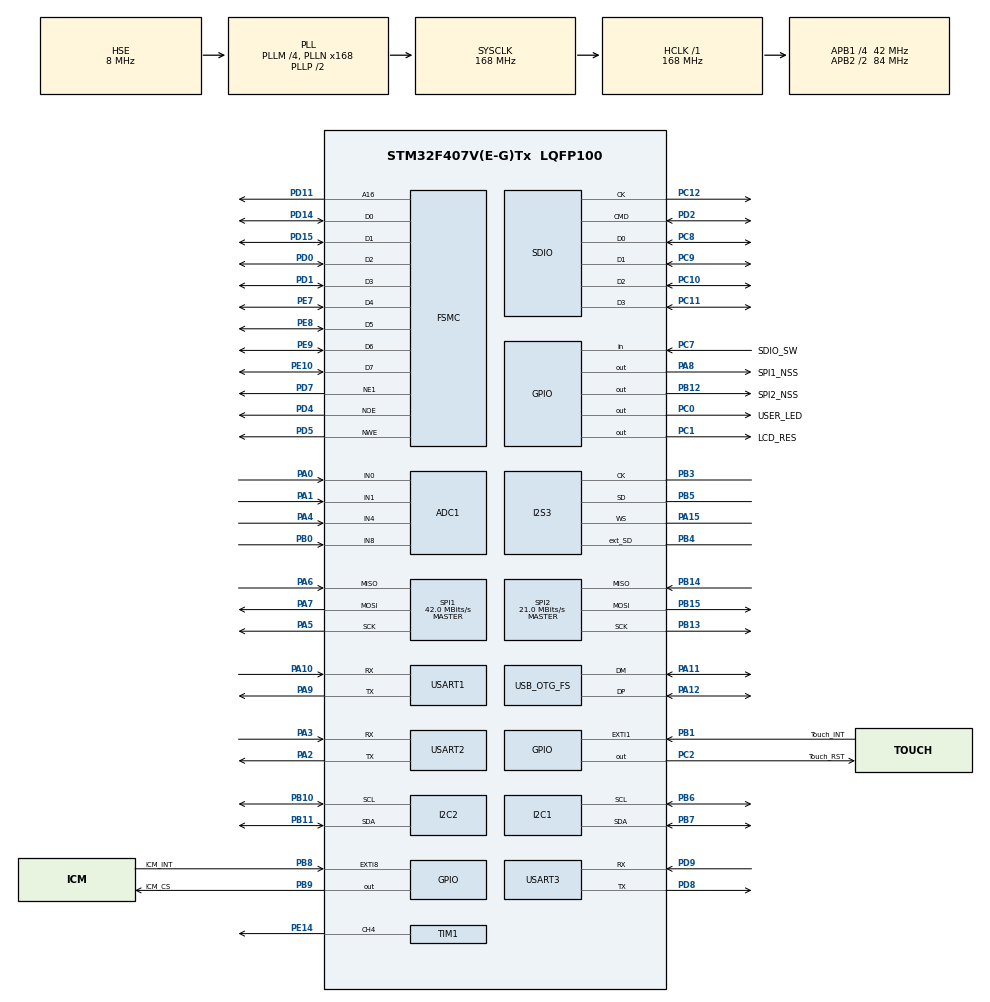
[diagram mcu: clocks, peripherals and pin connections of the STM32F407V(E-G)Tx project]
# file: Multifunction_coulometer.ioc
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ADC1.Channel-2\#ChannelRegularConversion=ADC_CHANNEL_0
ADC1.NbrOfConversionFlag=1
ADC1.Rank-2\#ChannelRegularConversion=1
ADC1.SamplingTime-2\#ChannelRegularConversion=ADC_SAMPLETIME_3CYCLES
ADC1.master=1
I2S3.ErrorAudioFreq=0.15 %
I2S3.FullDuplexMode=I2S_FULLDUPLEXMODE_ENABLE
I2S3.Instance=SPI$Index
I2S3.RealAudioFreq=8.012 KHz
I2S3.VirtualMode=I2S_MODE_MASTER
Mcu.Family=STM32F4
Mcu.Name=STM32F407V(E-G)Tx
Mcu.Package=LQFP100
NVIC.PriorityGroup=NVIC_PRIORITYGROUP_4
PA0-WKUP.Signal=ADCx_IN0
PA1.Signal=ADCx_IN1
PA10.Mode=Asynchronous
PA10.Signal=USART1_RX
PA11.Mode=Device_Only
PA11.Signal=USB_OTG_FS_DM
PA12.Mode=Device_Only
PA12.Signal=USB_OTG_FS_DP
PA13.Mode=Serial_Wire
PA13.Signal=SYS_JTMS-SWDIO
PA14.Mode=Serial_Wire
PA14.Signal=SYS_JTCK-SWCLK
PA15.Mode=Full_Duplex_Master
PA15.Signal=I2S3_WS
PA2.Mode=Asynchronous
PA2.Signal=USART2_TX
PA3.Mode=Asynchronous
PA3.Signal=USART2_RX
PA4.Signal=ADCx_IN4
PA5.Mode=Full_Duplex_Master
PA5.Signal=SPI1_SCK
PA6.Mode=Full_Duplex_Master
PA6.Signal=SPI1_MISO
PA7.Mode=Full_Duplex_Master
PA7.Signal=SPI1_MOSI
PA8.GPIO_Label=SPI1_NSS
PA8.Signal=GPIO_Output
PA9.Mode=Asynchronous
PA9.Signal=USART1_TX
PB0.Signal=ADCx_IN8
PB1.GPIO_Label=Touch_INT
PB1.Signal=GPXTI1
PB10.Mode=I2C
PB10.Signal=I2C2_SCL
PB11.Mode=I2C
PB11.Signal=I2C2_SDA
PB12.GPIO_Label=SPI2_NSS
PB12.Signal=GPIO_Output
PB13.Mode=Full_Duplex_Master
PB13.Signal=SPI2_SCK
PB14.Mode=Full_Duplex_Master
PB14.Signal=SPI2_MISO
PB15.Mode=Full_Duplex_Master
PB15.Signal=SPI2_MOSI
PB3.Mode=Full_Duplex_Master
PB3.Signal=I2S3_CK
PB4.Mode=Full_Duplex_Master
PB4.Signal=I2S3_ext_SD
PB5.Mode=Full_Duplex_Master
PB5.Signal=I2S3_SD
PB6.Mode=I2C
PB6.Signal=I2C1_SCL
PB7.Mode=I2C
PB7.Signal=I2C1_SDA
PB8.GPIO_Label=ICM_INT
PB8.Signal=GPXTI8
PB9.GPIO_Label=ICM_CS
PB9.Signal=GPIO_Output
PC0.GPIO_Label=USER_LED
PC0.GPIO_ModeDefaultOutputPP=GPIO_MODE_OUTPUT_PP
PC0.GPIO_PuPd=GPIO_PULLUP
PC0.GPIO_Speed=GPIO_SPEED_FREQ_VERY_HIGH
PC0.PinState=GPIO_PIN_SET
PC0.Signal=GPIO_Output
PC1.GPIO_Label=LCD_RES
PC1.Signal=GPIO_Output
PC10.Mode=SD_4_bits_Wide_bus
PC10.Signal=SDIO_D2
PC11.Mode=SD_4_bits_Wide_bus
PC11.Signal=SDIO_D3
PC12.Mode=SD_4_bits_Wide_bus
PC12.Signal=SDIO_CK
PC14-OSC32_IN.Mode=LSE-External-Oscillator
PC14-OSC32_IN.Signal=RCC_OSC32_IN
PC15-OSC32_OUT.Mode=LSE-External-Oscillator
PC15-OSC32_OUT.Signal=RCC_OSC32_OUT
PC2.GPIO_Label=Touch_RST
PC2.Signal=GPIO_Output
PC7.GPIO_Label=SDIO_SW
PC7.Signal=GPIO_Input
PC8.Mode=SD_4_bits_Wide_bus
PC8.Signal=SDIO_D0
PC9.Mode=SD_4_bits_Wide_bus
PC9.Signal=SDIO_D1
PD0.Mode=8b-d1
PD0.Signal=FSMC_D2
PD1.Mode=8b-d1
PD1.Signal=FSMC_D3
PD11.Mode=A16_1
PD11.Signal=FSMC_A16
PD14.Mode=8b-d1
PD14.Signal=FSMC_D0
PD15.Mode=8b-d1
PD15.Signal=FSMC_D1
PD2.Mode=SD_4_bits_Wide_bus
PD2.Signal=SDIO_CMD
PD4.Mode=Lcd1
PD4.Signal=FSMC_NOE
PD5.Mode=Lcd1
PD5.Signal=FSMC_NWE
PD7.Mode=NorPsramChipSelect1_1
PD7.Signal=FSMC_NE1
PD8.Mode=Asynchronous
PD8.Signal=USART3_TX
PD9.Mode=Asynchronous
PD9.Signal=USART3_RX
PE10.Mode=8b-d1
PE10.Signal=FSMC_D7
PE14.Signal=S_TIM1_CH4
PE7.Mode=8b-d1
PE7.Signal=FSMC_D4
PE8.Mode=8b-d1
PE8.Signal=FSMC_D5
PE9.Mode=8b-d1
PE9.Signal=FSMC_D6
PH0-OSC_IN.Mode=HSE-External-Oscillator
PH0-OSC_IN.Signal=RCC_OSC_IN
PH1-OSC_OUT.Mode=HSE-External-Oscillator
PH1-OSC_OUT.Signal=RCC_OSC_OUT
ProjectManager.HeapSize=0x200
ProjectManager.StackSize=0x400
ProjectManager.TargetToolchain=MDK-ARM V5.32
RCC.48MHZClocksFreq_Value=48000000
RCC.AHBFreq_Value=168000000
RCC.APB1CLKDivider=RCC_HCLK_DIV4
RCC.APB1Freq_Value=42000000
RCC.APB1TimFreq_Value=84000000
RCC.APB2CLKDivider=RCC_HCLK_DIV2
RCC.APB2Freq_Value=84000000
RCC.APB2TimFreq_Value=168000000
RCC.CortexFreq_Value=168000000
RCC.HCLKFreq_Value=168000000
RCC.HSE_VALUE=8000000
RCC.HSI_VALUE=16000000
RCC.PLLI2SN=50
RCC.PLLM=4
RCC.PLLN=168
RCC.PLLQ=7
RCC.SYSCLKFreq_VALUE=168000000
RCC.SYSCLKSource=RCC_SYSCLKSOURCE_PLLCLK
RCC.VCOOutputFreq_Value=336000000
SH.ADCx_IN0.0=ADC1_IN0,IN0
SH.ADCx_IN1.0=ADC1_IN1,IN1
SH.ADCx_IN4.0=ADC1_IN4,IN4
SH.ADCx_IN8.0=ADC1_IN8,IN8
SH.S_TIM1_CH4.0=TIM1_CH4,PWM Generation4 CH4
SPI1.CalculateBaudRate=42.0 MBits/s
SPI1.Direction=SPI_DIRECTION_2LINES
SPI1.Mode=SPI_MODE_MASTER
SPI1.VirtualType=VM_MASTER
SPI2.CalculateBaudRate=21.0 MBits/s
SPI2.Direction=SPI_DIRECTION_2LINES
SPI2.Mode=SPI_MODE_MASTER
SPI2.VirtualType=VM_MASTER
TIM1.Channel-PWM\ Generation4\ CH4=TIM_CHANNEL_4
USART1.VirtualMode=VM_ASYNC
USART2.VirtualMode=VM_ASYNC
USART3.VirtualMode=VM_ASYNC
USB_OTG_FS.VirtualMode=Device_Only
board=custom

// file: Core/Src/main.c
/* USER CODE BEGIN Header */
/**
  ******************************************************************************
  * @file           : main.c
  * @brief          : Main program body
  ******************************************************************************
  * @attention
  *
  * Copyright (c) 2022 STMicroelectronics.
  * All rights reserved.
  *
  * This software is licensed under terms that can be found in the LICENSE file
  * in the root directory of this software component.
  * If no LICENSE file comes with this software, it is provided AS-IS.
  *
  ******************************************************************************
  */
/* USER CODE END Header */
#include "main.h"
#include "adc.h"
#include "i2c.h"
#include "i2s.h"
#include "sdio.h"
#include "spi.h"
#include "tim.h"
#include "usart.h"
#include "usb_otg.h"
#include "gpio.h"
#include "fsmc.h"

void SystemClock_Config(void);

int main(void)
{

  /* MCU Configuration--------------------------------------------------------*/

  /* Reset of all peripherals, Initializes the Flash interface and the Systick. */
  HAL_Init();

  /* Configure the system clock */
  SystemClock_Config();

  /* Initialize all configured peripherals */
  MX_GPIO_Init();
  MX_FSMC_Init();
  MX_I2C1_Init();
  MX_I2C2_Init();
  MX_I2S3_Init();
  MX_SDIO_SD_Init();
  MX_SPI1_Init();
  MX_SPI2_Init();
  MX_USART1_UART_Init();
  MX_USART2_UART_Init();
  MX_USART3_UART_Init();
  MX_ADC1_Init();
  MX_USB_OTG_FS_PCD_Init();
  MX_TIM1_Init();

  /* Infinite loop */
  /* USER CODE BEGIN WHILE */
  while (1)
  {
	  HAL_GPIO_WritePin(USER_LED_GPIO_Port, USER_LED_Pin, GPIO_PIN_RESET);
	  HAL_Delay(500);
	  HAL_GPIO_WritePin(USER_LED_GPIO_Port, USER_LED_Pin, GPIO_PIN_SET);
	  HAL_Delay(500);
    /* USER CODE END WHILE */

	}
}

void SystemClock_Config(void)
{
  RCC_OscInitTypeDef RCC_OscInitStruct = {0};
  RCC_ClkInitTypeDef RCC_ClkInitStruct = {0};

  /** Configure the main internal regulator output voltage
  */
  __HAL_RCC_PWR_CLK_ENABLE();
  __HAL_PWR_VOLTAGESCALING_CONFIG(PWR_REGULATOR_VOLTAGE_SCALE1);

  /** Initializes the RCC Oscillators according to the specified parameters
  * in the RCC_OscInitTypeDef structure.
  */
  RCC_OscInitStruct.OscillatorType = RCC_OSCILLATORTYPE_HSE;
  RCC_OscInitStruct.HSEState = RCC_HSE_ON;
  RCC_OscInitStruct.PLL.PLLState = RCC_PLL_ON;
  RCC_OscInitStruct.PLL.PLLSource = RCC_PLLSOURCE_HSE;
  RCC_OscInitStruct.PLL.PLLM = 4;
  RCC_OscInitStruct.PLL.PLLN = 168;
  RCC_OscInitStruct.PLL.PLLP = RCC_PLLP_DIV2;
  RCC_OscInitStruct.PLL.PLLQ = 7;
  if (HAL_RCC_OscConfig(&RCC_OscInitStruct) != HAL_OK)
  {
    Error_Handler();
  }

  /** Initializes the CPU, AHB and APB buses clocks
  */
  RCC_ClkInitStruct.ClockType = RCC_CLOCKTYPE_HCLK|RCC_CLOCKTYPE_SYSCLK
                              |RCC_CLOCKTYPE_PCLK1|RCC_CLOCKTYPE_PCLK2;
  RCC_ClkInitStruct.SYSCLKSource = RCC_SYSCLKSOURCE_PLLCLK;
  RCC_ClkInitStruct.AHBCLKDivider = RCC_SYSCLK_DIV1;
  RCC_ClkInitStruct.APB1CLKDivider = RCC_HCLK_DIV4;
  RCC_ClkInitStruct.APB2CLKDivider = RCC_HCLK_DIV2;

  if (HAL_RCC_ClockConfig(&RCC_ClkInitStruct, FLASH_LATENCY_5) != HAL_OK)
  {
    Error_Handler();
  }
}

void Error_Handler(void)
{
  __disable_irq();
  while (1)
  {
  }
}
